VERSION ""

NS_ :

BS_:

BU_: XXX

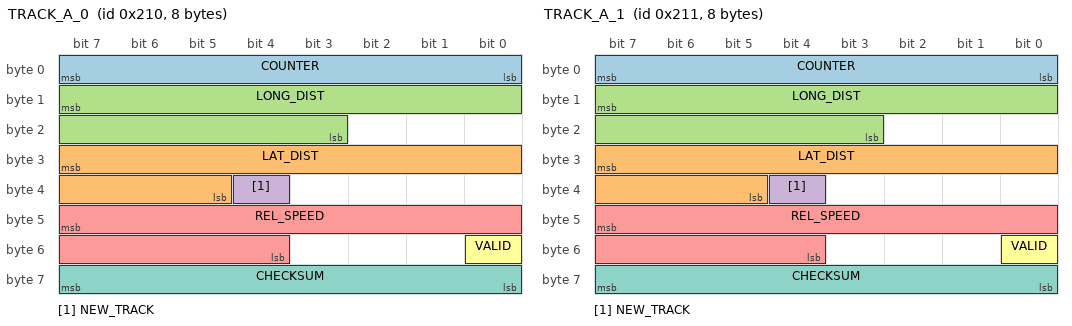
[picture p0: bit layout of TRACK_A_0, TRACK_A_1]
BO_ 528 TRACK_A_0: 8 XXX
 SG_ COUNTER : 7|8@0+ (1,0) [0|255] "" XXX
 SG_ LAT_DIST : 31|11@0- (0.04,0) [-50|50] "m" XXX
 SG_ LONG_DIST : 15|13@0+ (0.04,0) [0|300] "m" XXX
 SG_ NEW_TRACK : 36|1@0+ (1,0) [0|1] "" XXX
 SG_ REL_SPEED : 47|12@0- (0.025,0) [-100|100] "m/s" XXX
 SG_ VALID : 48|1@0+ (1,0) [0|1] "" XXX
 SG_ CHECKSUM : 63|8@0+ (1,0) [0|255] "" XXX

BO_ 529 TRACK_A_1: 8 XXX
 SG_ COUNTER : 7|8@0+ (1,0) [0|255] "" XXX
 SG_ LAT_DIST : 31|11@0- (0.04,0) [-50|50] "m" XXX
 SG_ LONG_DIST : 15|13@0+ (0.04,0) [0|300] "m" XXX
 SG_ NEW_TRACK : 36|1@0+ (1,0) [0|1] "" XXX
 SG_ REL_SPEED : 47|12@0- (0.025,0) [-100|100] "m/s" XXX
 SG_ VALID : 48|1@0+ (1,0) [0|1] "" XXX
 SG_ CHECKSUM : 63|8@0+ (1,0) [0|255] "" XXX

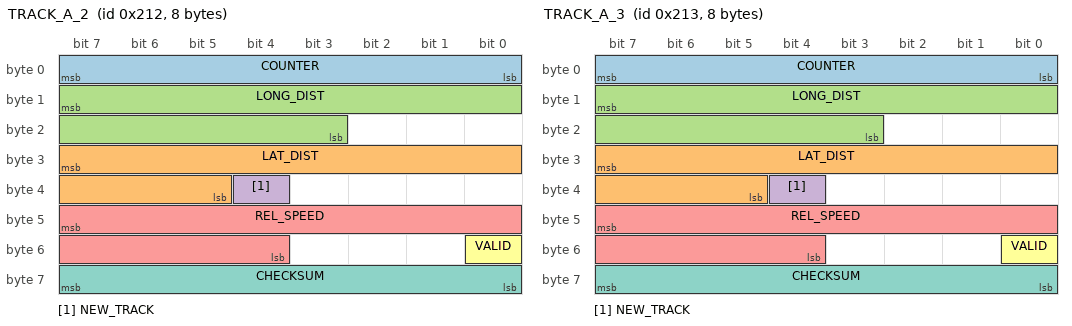
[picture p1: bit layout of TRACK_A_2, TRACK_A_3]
BO_ 530 TRACK_A_2: 8 XXX
 SG_ COUNTER : 7|8@0+ (1,0) [0|255] "" XXX
 SG_ LAT_DIST : 31|11@0- (0.04,0) [-50|50] "m" XXX
 SG_ LONG_DIST : 15|13@0+ (0.04,0) [0|300] "m" XXX
 SG_ NEW_TRACK : 36|1@0+ (1,0) [0|1] "" XXX
 SG_ REL_SPEED : 47|12@0- (0.025,0) [-100|100] "m/s" XXX
 SG_ VALID : 48|1@0+ (1,0) [0|1] "" XXX
 SG_ CHECKSUM : 63|8@0+ (1,0) [0|255] "" XXX

BO_ 531 TRACK_A_3: 8 XXX
 SG_ COUNTER : 7|8@0+ (1,0) [0|255] "" XXX
 SG_ LAT_DIST : 31|11@0- (0.04,0) [-50|50] "m" XXX
 SG_ LONG_DIST : 15|13@0+ (0.04,0) [0|300] "m" XXX
 SG_ NEW_TRACK : 36|1@0+ (1,0) [0|1] "" XXX
 SG_ REL_SPEED : 47|12@0- (0.025,0) [-100|100] "m/s" XXX
 SG_ VALID : 48|1@0+ (1,0) [0|1] "" XXX
 SG_ CHECKSUM : 63|8@0+ (1,0) [0|255] "" XXX

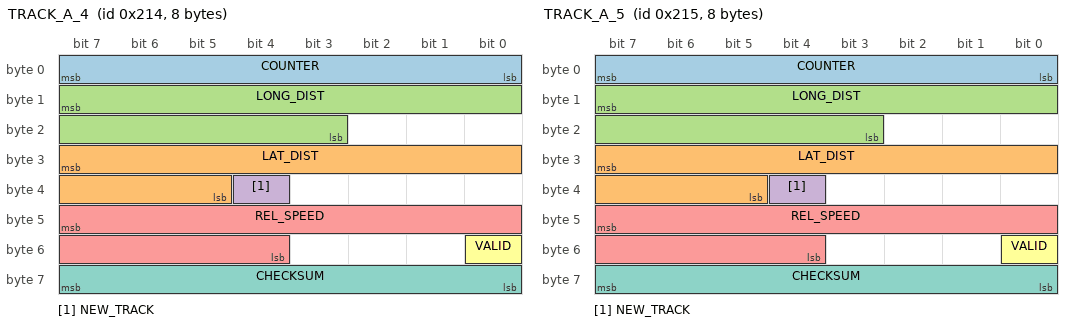
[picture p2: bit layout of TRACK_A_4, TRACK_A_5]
BO_ 532 TRACK_A_4: 8 XXX
 SG_ COUNTER : 7|8@0+ (1,0) [0|255] "" XXX
 SG_ LAT_DIST : 31|11@0- (0.04,0) [-50|50] "m" XXX
 SG_ LONG_DIST : 15|13@0+ (0.04,0) [0|300] "m" XXX
 SG_ NEW_TRACK : 36|1@0+ (1,0) [0|1] "" XXX
 SG_ REL_SPEED : 47|12@0- (0.025,0) [-100|100] "m/s" XXX
 SG_ VALID : 48|1@0+ (1,0) [0|1] "" XXX
 SG_ CHECKSUM : 63|8@0+ (1,0) [0|255] "" XXX

BO_ 533 TRACK_A_5: 8 XXX
 SG_ COUNTER : 7|8@0+ (1,0) [0|255] "" XXX
 SG_ LAT_DIST : 31|11@0- (0.04,0) [-50|50] "m" XXX
 SG_ LONG_DIST : 15|13@0+ (0.04,0) [0|300] "m" XXX
 SG_ NEW_TRACK : 36|1@0+ (1,0) [0|1] "" XXX
 SG_ REL_SPEED : 47|12@0- (0.025,0) [-100|100] "m/s" XXX
 SG_ VALID : 48|1@0+ (1,0) [0|1] "" XXX
 SG_ CHECKSUM : 63|8@0+ (1,0) [0|255] "" XXX

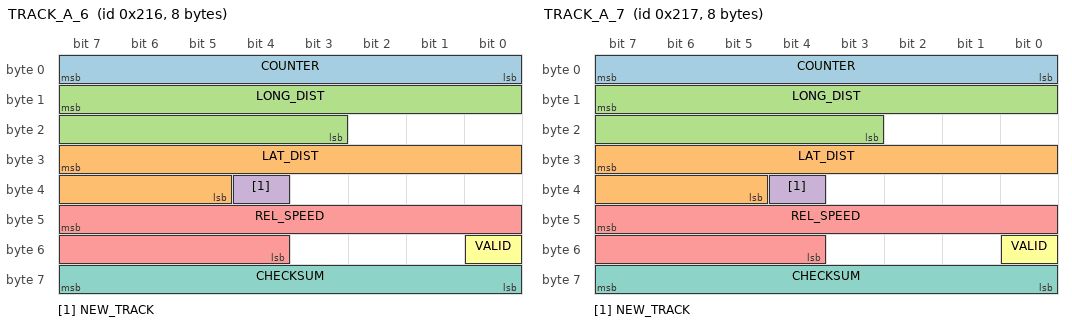
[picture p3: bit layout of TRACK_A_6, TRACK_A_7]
BO_ 534 TRACK_A_6: 8 XXX
 SG_ COUNTER : 7|8@0+ (1,0) [0|255] "" XXX
 SG_ LAT_DIST : 31|11@0- (0.04,0) [-50|50] "m" XXX
 SG_ LONG_DIST : 15|13@0+ (0.04,0) [0|300] "m" XXX
 SG_ NEW_TRACK : 36|1@0+ (1,0) [0|1] "" XXX
 SG_ REL_SPEED : 47|12@0- (0.025,0) [-100|100] "m/s" XXX
 SG_ VALID : 48|1@0+ (1,0) [0|1] "" XXX
 SG_ CHECKSUM : 63|8@0+ (1,0) [0|255] "" XXX

BO_ 535 TRACK_A_7: 8 XXX
 SG_ COUNTER : 7|8@0+ (1,0) [0|255] "" XXX
 SG_ LAT_DIST : 31|11@0- (0.04,0) [-50|50] "m" XXX
 SG_ LONG_DIST : 15|13@0+ (0.04,0) [0|300] "m" XXX
 SG_ NEW_TRACK : 36|1@0+ (1,0) [0|1] "" XXX
 SG_ REL_SPEED : 47|12@0- (0.025,0) [-100|100] "m/s" XXX
 SG_ VALID : 48|1@0+ (1,0) [0|1] "" XXX
 SG_ CHECKSUM : 63|8@0+ (1,0) [0|255] "" XXX

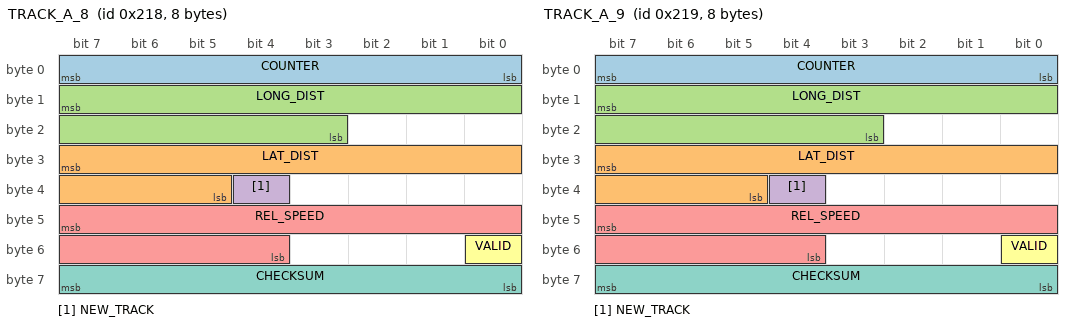
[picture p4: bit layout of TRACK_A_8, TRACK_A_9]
BO_ 536 TRACK_A_8: 8 XXX
 SG_ COUNTER : 7|8@0+ (1,0) [0|255] "" XXX
 SG_ LAT_DIST : 31|11@0- (0.04,0) [-50|50] "m" XXX
 SG_ LONG_DIST : 15|13@0+ (0.04,0) [0|300] "m" XXX
 SG_ NEW_TRACK : 36|1@0+ (1,0) [0|1] "" XXX
 SG_ REL_SPEED : 47|12@0- (0.025,0) [-100|100] "m/s" XXX
 SG_ VALID : 48|1@0+ (1,0) [0|1] "" XXX
 SG_ CHECKSUM : 63|8@0+ (1,0) [0|255] "" XXX

BO_ 537 TRACK_A_9: 8 XXX
 SG_ COUNTER : 7|8@0+ (1,0) [0|255] "" XXX
 SG_ LAT_DIST : 31|11@0- (0.04,0) [-50|50] "m" XXX
 SG_ LONG_DIST : 15|13@0+ (0.04,0) [0|300] "m" XXX
 SG_ NEW_TRACK : 36|1@0+ (1,0) [0|1] "" XXX
 SG_ REL_SPEED : 47|12@0- (0.025,0) [-100|100] "m/s" XXX
 SG_ VALID : 48|1@0+ (1,0) [0|1] "" XXX
 SG_ CHECKSUM : 63|8@0+ (1,0) [0|255] "" XXX

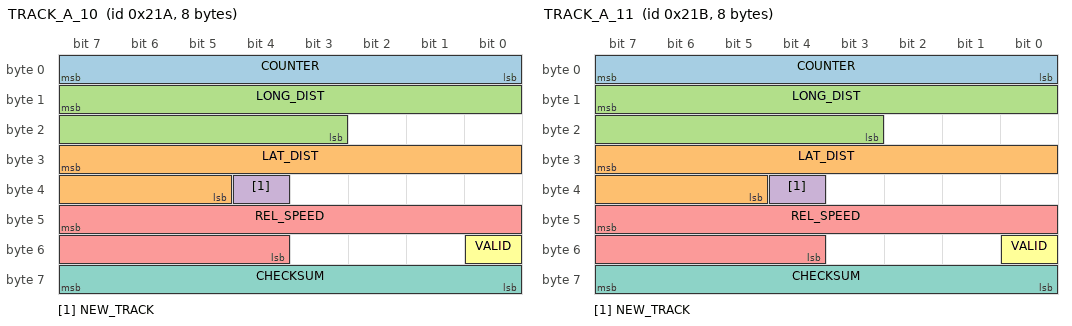
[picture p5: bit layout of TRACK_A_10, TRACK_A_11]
BO_ 538 TRACK_A_10: 8 XXX
 SG_ COUNTER : 7|8@0+ (1,0) [0|255] "" XXX
 SG_ LAT_DIST : 31|11@0- (0.04,0) [-50|50] "m" XXX
 SG_ LONG_DIST : 15|13@0+ (0.04,0) [0|300] "m" XXX
 SG_ NEW_TRACK : 36|1@0+ (1,0) [0|1] "" XXX
 SG_ REL_SPEED : 47|12@0- (0.025,0) [-100|100] "m/s" XXX
 SG_ VALID : 48|1@0+ (1,0) [0|1] "" XXX
 SG_ CHECKSUM : 63|8@0+ (1,0) [0|255] "" XXX

BO_ 539 TRACK_A_11: 8 XXX
 SG_ COUNTER : 7|8@0+ (1,0) [0|255] "" XXX
 SG_ LAT_DIST : 31|11@0- (0.04,0) [-50|50] "m" XXX
 SG_ LONG_DIST : 15|13@0+ (0.04,0) [0|300] "m" XXX
 SG_ NEW_TRACK : 36|1@0+ (1,0) [0|1] "" XXX
 SG_ REL_SPEED : 47|12@0- (0.025,0) [-100|100] "m/s" XXX
 SG_ VALID : 48|1@0+ (1,0) [0|1] "" XXX
 SG_ CHECKSUM : 63|8@0+ (1,0) [0|255] "" XXX

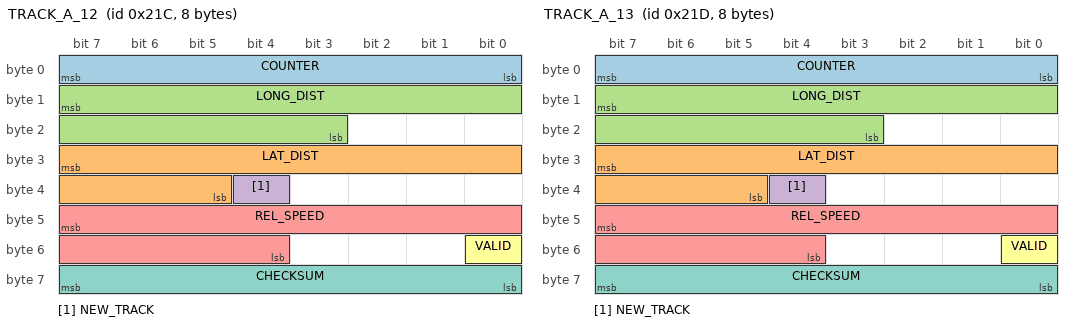
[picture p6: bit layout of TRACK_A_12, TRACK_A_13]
BO_ 540 TRACK_A_12: 8 XXX
 SG_ COUNTER : 7|8@0+ (1,0) [0|255] "" XXX
 SG_ LAT_DIST : 31|11@0- (0.04,0) [-50|50] "m" XXX
 SG_ LONG_DIST : 15|13@0+ (0.04,0) [0|300] "m" XXX
 SG_ NEW_TRACK : 36|1@0+ (1,0) [0|1] "" XXX
 SG_ REL_SPEED : 47|12@0- (0.025,0) [-100|100] "m/s" XXX
 SG_ VALID : 48|1@0+ (1,0) [0|1] "" XXX
 SG_ CHECKSUM : 63|8@0+ (1,0) [0|255] "" XXX

BO_ 541 TRACK_A_13: 8 XXX
 SG_ COUNTER : 7|8@0+ (1,0) [0|255] "" XXX
 SG_ LAT_DIST : 31|11@0- (0.04,0) [-50|50] "m" XXX
 SG_ LONG_DIST : 15|13@0+ (0.04,0) [0|300] "m" XXX
 SG_ NEW_TRACK : 36|1@0+ (1,0) [0|1] "" XXX
 SG_ REL_SPEED : 47|12@0- (0.025,0) [-100|100] "m/s" XXX
 SG_ VALID : 48|1@0+ (1,0) [0|1] "" XXX
 SG_ CHECKSUM : 63|8@0+ (1,0) [0|255] "" XXX

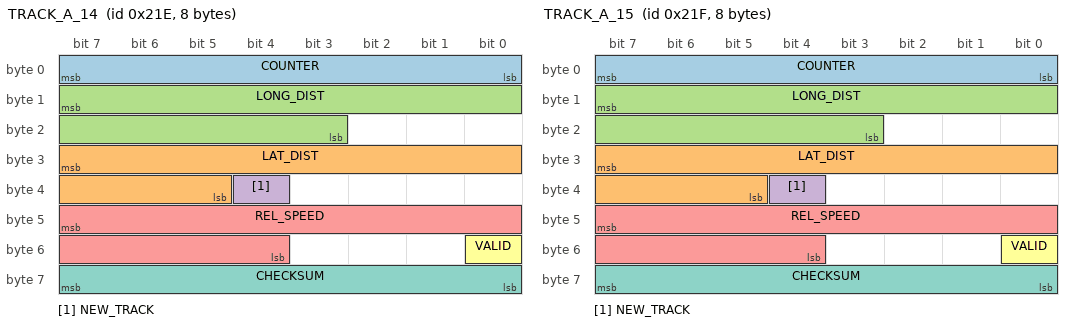
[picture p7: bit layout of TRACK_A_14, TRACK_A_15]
BO_ 542 TRACK_A_14: 8 XXX
 SG_ COUNTER : 7|8@0+ (1,0) [0|255] "" XXX
 SG_ LAT_DIST : 31|11@0- (0.04,0) [-50|50] "m" XXX
 SG_ LONG_DIST : 15|13@0+ (0.04,0) [0|300] "m" XXX
 SG_ NEW_TRACK : 36|1@0+ (1,0) [0|1] "" XXX
 SG_ REL_SPEED : 47|12@0- (0.025,0) [-100|100] "m/s" XXX
 SG_ VALID : 48|1@0+ (1,0) [0|1] "" XXX
 SG_ CHECKSUM : 63|8@0+ (1,0) [0|255] "" XXX

BO_ 543 TRACK_A_15: 8 XXX
 SG_ COUNTER : 7|8@0+ (1,0) [0|255] "" XXX
 SG_ LAT_DIST : 31|11@0- (0.04,0) [-50|50] "m" XXX
 SG_ LONG_DIST : 15|13@0+ (0.04,0) [0|300] "m" XXX
 SG_ NEW_TRACK : 36|1@0+ (1,0) [0|1] "" XXX
 SG_ REL_SPEED : 47|12@0- (0.025,0) [-100|100] "m/s" XXX
 SG_ VALID : 48|1@0+ (1,0) [0|1] "" XXX
 SG_ CHECKSUM : 63|8@0+ (1,0) [0|255] "" XXX

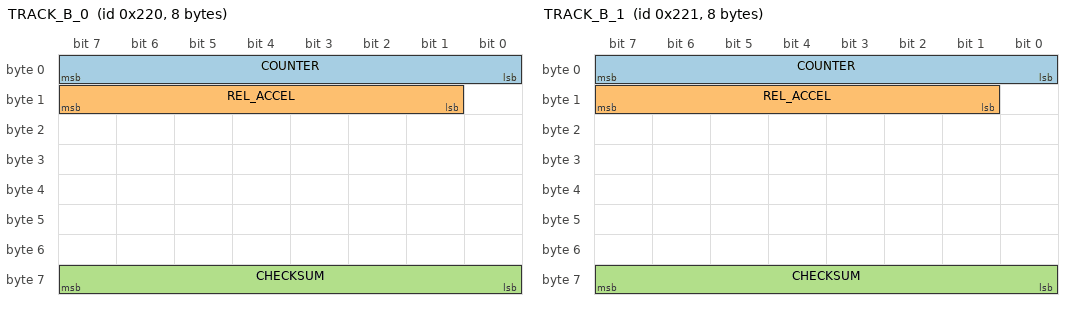
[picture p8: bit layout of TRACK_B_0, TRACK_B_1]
BO_ 544 TRACK_B_0: 8 XXX
 SG_ COUNTER : 7|8@0+ (1,0) [0|255] "" XXX
 SG_ REL_ACCEL : 15|7@0- (1,0) [-64|63] "" XXX
 SG_ CHECKSUM : 63|8@0+ (1,0) [0|255] "" XXX

BO_ 545 TRACK_B_1: 8 XXX
 SG_ COUNTER : 7|8@0+ (1,0) [0|255] "" XXX
 SG_ REL_ACCEL : 15|7@0- (1,0) [-64|63] "" XXX
 SG_ CHECKSUM : 63|8@0+ (1,0) [0|255] "" XXX

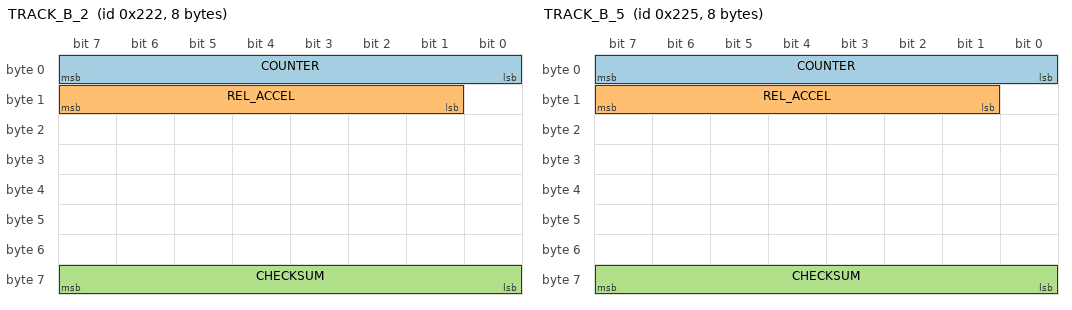
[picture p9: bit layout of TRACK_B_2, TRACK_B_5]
BO_ 546 TRACK_B_2: 8 XXX
 SG_ COUNTER : 7|8@0+ (1,0) [0|255] "" XXX
 SG_ REL_ACCEL : 15|7@0- (1,0) [-64|63] "" XXX
 SG_ CHECKSUM : 63|8@0+ (1,0) [0|255] "" XXX

BO_ 547 undefined: 8 XXX

BO_ 548 undefined: 8 XXX

BO_ 549 TRACK_B_5: 8 XXX
 SG_ COUNTER : 7|8@0+ (1,0) [0|255] "" XXX
 SG_ REL_ACCEL : 15|7@0- (1,0) [-64|63] "" XXX
 SG_ CHECKSUM : 63|8@0+ (1,0) [0|255] "" XXX

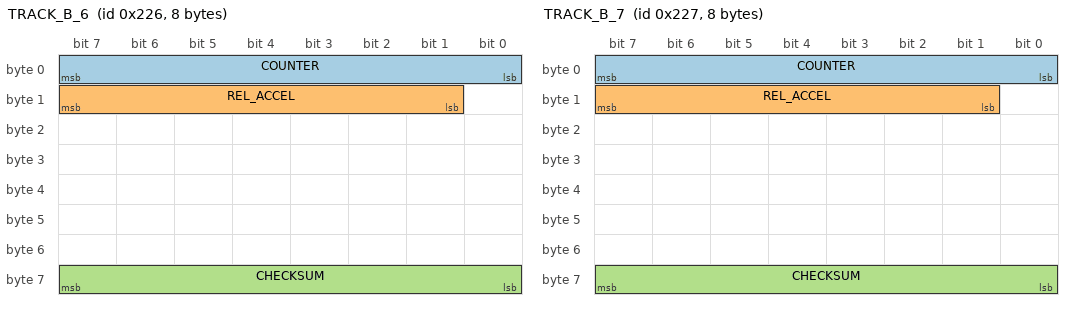
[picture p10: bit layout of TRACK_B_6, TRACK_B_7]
BO_ 550 TRACK_B_6: 8 XXX
 SG_ COUNTER : 7|8@0+ (1,0) [0|255] "" XXX
 SG_ REL_ACCEL : 15|7@0- (1,0) [-64|63] "" XXX
 SG_ CHECKSUM : 63|8@0+ (1,0) [0|255] "" XXX

BO_ 551 TRACK_B_7: 8 XXX
 SG_ COUNTER : 7|8@0+ (1,0) [0|255] "" XXX
 SG_ REL_ACCEL : 15|7@0- (1,0) [-64|63] "" XXX
 SG_ CHECKSUM : 63|8@0+ (1,0) [0|255] "" XXX

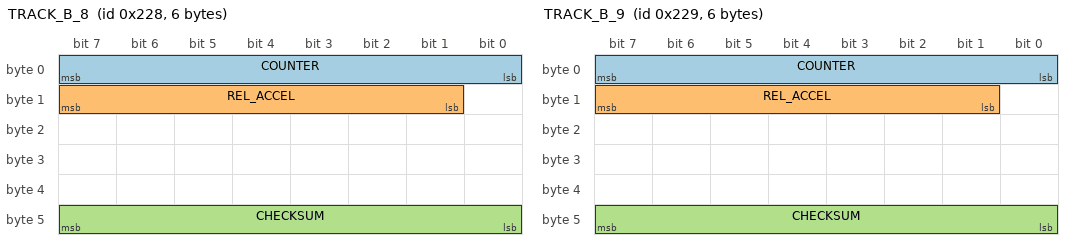
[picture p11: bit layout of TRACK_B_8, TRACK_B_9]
BO_ 552 TRACK_B_8: 6 XXX
 SG_ COUNTER : 7|8@0+ (1,0) [0|255] "" XXX
 SG_ REL_ACCEL : 15|7@0- (1,0) [-64|63] "" XXX
 SG_ CHECKSUM : 47|8@0+ (1,0) [0|255] "" XXX

BO_ 553 TRACK_B_9: 6 XXX
 SG_ COUNTER : 7|8@0+ (1,0) [0|255] "" XXX
 SG_ REL_ACCEL : 15|7@0- (1,0) [-64|63] "" XXX
 SG_ CHECKSUM : 47|8@0+ (1,0) [0|255] "" XXX

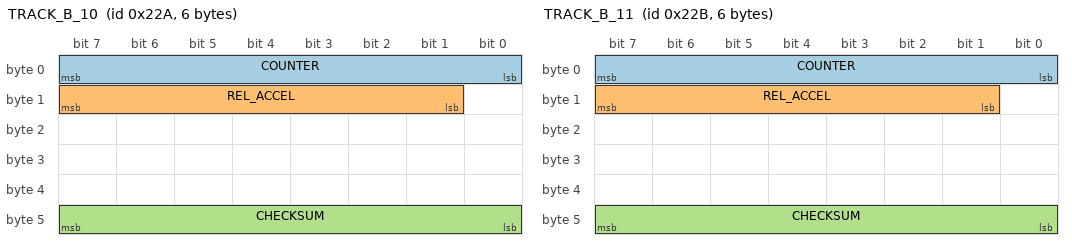
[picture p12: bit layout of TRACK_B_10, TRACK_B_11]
BO_ 554 TRACK_B_10: 6 XXX
 SG_ COUNTER : 7|8@0+ (1,0) [0|255] "" XXX
 SG_ REL_ACCEL : 15|7@0- (1,0) [-64|63] "" XXX
 SG_ CHECKSUM : 47|8@0+ (1,0) [0|255] "" XXX

BO_ 555 TRACK_B_11: 6 XXX
 SG_ COUNTER : 7|8@0+ (1,0) [0|255] "" XXX
 SG_ REL_ACCEL : 15|7@0- (1,0) [-64|63] "" XXX
 SG_ CHECKSUM : 47|8@0+ (1,0) [0|255] "" XXX

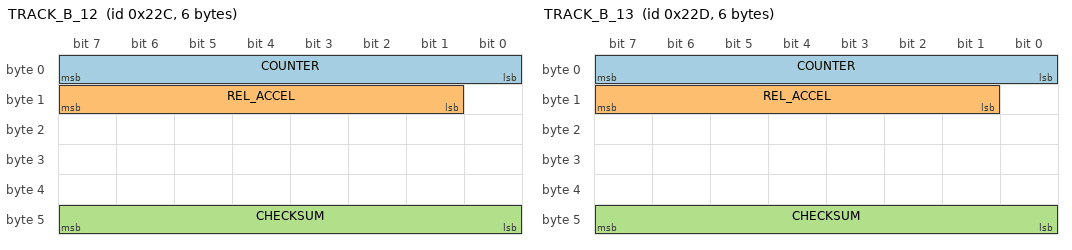
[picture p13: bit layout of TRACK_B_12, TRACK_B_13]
BO_ 556 TRACK_B_12: 6 XXX
 SG_ COUNTER : 7|8@0+ (1,0) [0|255] "" XXX
 SG_ REL_ACCEL : 15|7@0- (1,0) [-64|63] "" XXX
 SG_ CHECKSUM : 47|8@0+ (1,0) [0|255] "" XXX

BO_ 557 TRACK_B_13: 6 XXX
 SG_ COUNTER : 7|8@0+ (1,0) [0|255] "" XXX
 SG_ REL_ACCEL : 15|7@0- (1,0) [-64|63] "" XXX
 SG_ CHECKSUM : 47|8@0+ (1,0) [0|255] "" XXX

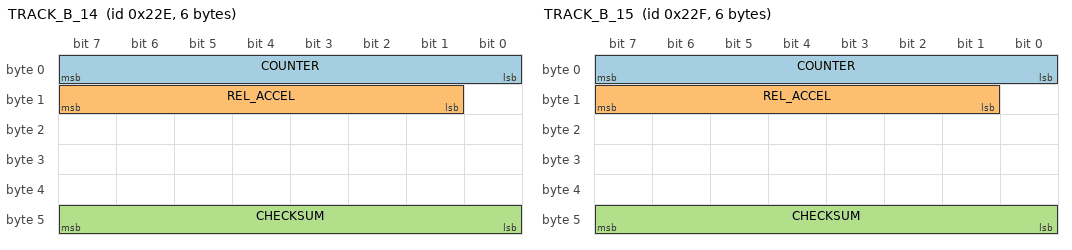
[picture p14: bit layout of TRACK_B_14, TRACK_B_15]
BO_ 558 TRACK_B_14: 6 XXX
 SG_ COUNTER : 7|8@0+ (1,0) [0|255] "" XXX
 SG_ REL_ACCEL : 15|7@0- (1,0) [-64|63] "" XXX
 SG_ CHECKSUM : 47|8@0+ (1,0) [0|255] "" XXX

BO_ 559 TRACK_B_15: 6 XXX
 SG_ COUNTER : 7|8@0+ (1,0) [0|255] "" XXX
 SG_ REL_ACCEL : 15|7@0- (1,0) [-64|63] "" XXX
 SG_ CHECKSUM : 47|8@0+ (1,0) [0|255] "" XXX

BO_ 1552 NEW_MSG_1: 8 XXX
 SG_ SPEED_LOWRES : 16|8@1+ (1,0) [0|255] "km/h?" XXX

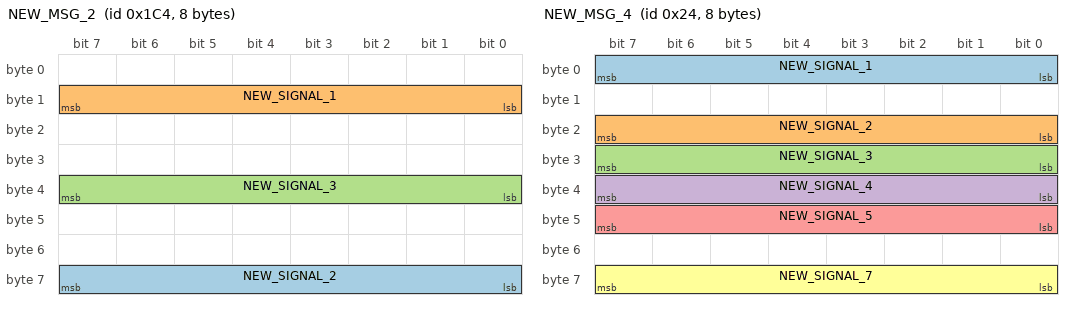
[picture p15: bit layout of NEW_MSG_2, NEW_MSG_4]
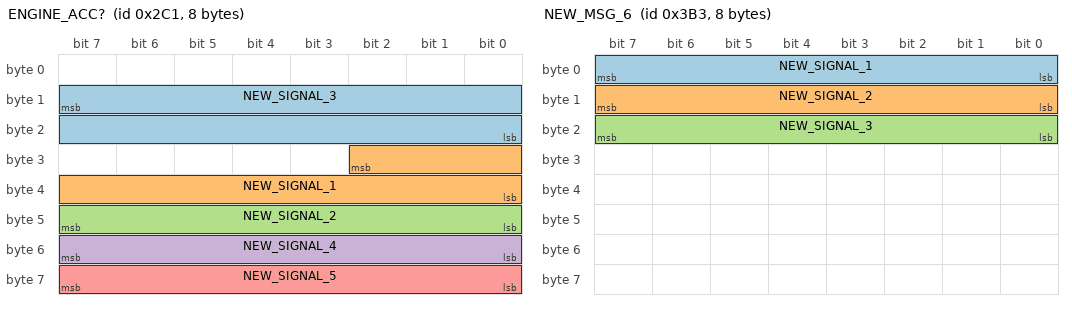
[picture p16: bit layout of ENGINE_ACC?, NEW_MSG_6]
BO_ 452 NEW_MSG_2: 8 XXX
 SG_ NEW_SIGNAL_2 : 56|8@1+ (1,0) [0|255] "" XXX
 SG_ NEW_SIGNAL_1 : 8|8@1+ (1,0) [0|255] "" XXX
 SG_ NEW_SIGNAL_3 : 39|8@0+ (1,0) [0|255] "" XXX

BO_ 37 NEW_MSG_3: 8 XXX
 SG_ NEW_SIGNAL_1 : 15|8@0+ (1,0) [0|255] "" XXX
 SG_ NEW_SIGNAL_2 : 47|8@0+ (1,0) [0|255] "" XXX

BO_ 36 NEW_MSG_4: 8 XXX
 SG_ NEW_SIGNAL_1 : 7|8@0+ (1,0) [0|255] "" XXX
 SG_ NEW_SIGNAL_2 : 23|8@0+ (1,0) [0|255] "" XXX
 SG_ NEW_SIGNAL_3 : 31|8@0+ (1,0) [0|255] "" XXX
 SG_ NEW_SIGNAL_4 : 39|8@0+ (1,0) [0|255] "" XXX
 SG_ NEW_SIGNAL_5 : 47|8@0+ (1,0) [0|255] "" XXX
 SG_ NEW_SIGNAL_7 : 63|8@0+ (1,0) [0|255] "" XXX

BO_ 705 ENGINE_ACC?: 8 XXX
 SG_ NEW_SIGNAL_3 : 15|16@0+ (1,0) [0|255] "" XXX
 SG_ NEW_SIGNAL_1 : 26|11@0+ (1,0) [0|255] "" XXX
 SG_ NEW_SIGNAL_2 : 47|8@0+ (1,0) [0|255] "" XXX
 SG_ NEW_SIGNAL_4 : 55|8@0+ (1,0) [0|255] "" XXX
 SG_ NEW_SIGNAL_5 : 63|8@0+ (1,0) [0|255] "" XXX

BO_ 947 NEW_MSG_6: 8 XXX
 SG_ NEW_SIGNAL_1 : 7|8@0+ (1,0) [0|255] "" XXX
 SG_ NEW_SIGNAL_2 : 15|8@0+ (1,0) [0|255] "" XXX
 SG_ NEW_SIGNAL_3 : 23|8@0+ (1,0) [0|255] "" XXX

BO_ 955 NEW_MSG_7: 8 XXX
 SG_ NEW_SIGNAL_1 : 23|8@0+ (1,0) [0|255] "" XXX

BO_ 1595 CONTAINS_TIME: 8 XXX
 SG_ TIME_ON : 55|16@0+ (0.1,0) [0|65535] "" XXX

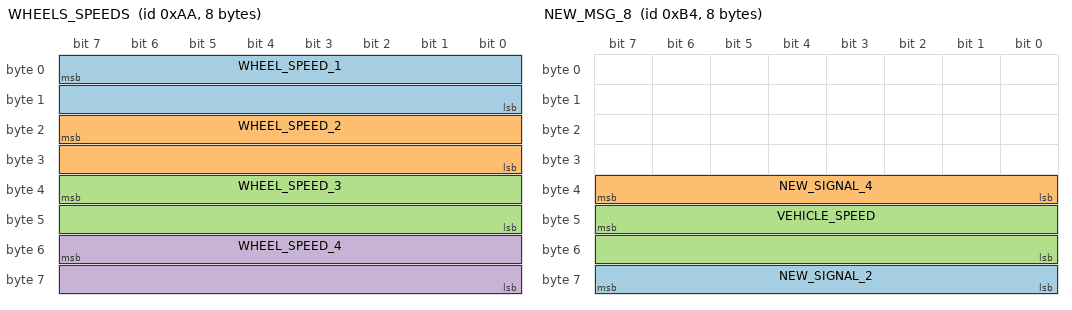
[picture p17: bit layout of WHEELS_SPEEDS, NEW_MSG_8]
BO_ 170 WHEELS_SPEEDS: 8 XXX
 SG_ WHEEL_SPEED_1 : 7|16@0+ (0.01,-67.67) [0|65535] "" XXX
 SG_ WHEEL_SPEED_2 : 23|16@0+ (0.01,-67.67) [0|65535] "km/h?" XXX
 SG_ WHEEL_SPEED_3 : 39|16@0+ (0.01,-67.67) [0|65535] "km/h" XXX
 SG_ WHEEL_SPEED_4 : 55|16@0+ (0.01,-67.67) [0|65535] "km/h" XXX

BO_ 180 NEW_MSG_8: 8 XXX
 SG_ NEW_SIGNAL_2 : 63|8@0+ (1,0) [0|255] "" XXX
 SG_ NEW_SIGNAL_4 : 39|8@0+ (1,0) [0|255] "" XXX
 SG_ VEHICLE_SPEED : 47|16@0+ (0.01,0) [0|255] "km/h?" XXX

BO_ 186 NEW_MSG_9: 8 XXX
 SG_ NEW_SIGNAL_1 : 7|16@0+ (1,0) [0|255] "" XXX
 SG_ NEW_SIGNAL_2 : 31|8@0+ (1,0) [0|255] "" XXX

BO_ 565 NEW_MSG_10: 8 XXX

BO_ 464 NEW_MSG_11: 8 XXX

BO_ 426 NEW_MSG_5: 8 XXX
 SG_ NEW_SIGNAL_1 : 47|8@0+ (1,0) [0|255] "" XXX

BO_ 906 NEW_MSG_12: 8 XXX
 SG_ NEW_SIGNAL_1 : 7|8@0+ (1,0) [0|255] "" XXX

BO_ 979 NEW_MSG_13: 8 XXX
 SG_ NEW_SIGNAL_1 : 7|8@0+ (1,0) [0|255] "" XXX
 SG_ NEW_SIGNAL_2 : 15|8@0+ (1,0) [0|255] "" XXX

BO_ 1600 NEW_MSG_14: 8 XXX
 SG_ NEW_SIGNAL_1 : 47|8@0+ (1,0) [0|1] "" XXX

CM_ SG_ 1552 SPEED_LOWRES "Looks like positive speed";
CM_ SG_ 37 NEW_SIGNAL_1 "vehicle orientation? (Z axis, noisy)";
CM_ SG_ 705 NEW_SIGNAL_3 "Maybe not well defined, RPM engine?";
CM_ SG_ 705 NEW_SIGNAL_1 "Maybe not welll defined, acceleration?";
CM_ SG_ 1595 TIME_ON "linear to seconds, must find bounds";
CM_ SG_ 170 WHEEL_SPEED_1 "TB verified";
CM_ SG_ 170 WHEEL_SPEED_2 "to be verified";
CM_ SG_ 170 WHEEL_SPEED_3 "to be verified";
CM_ SG_ 170 WHEEL_SPEED_4 "to be verified";
CM_ SG_ 180 VEHICLE_SPEED "To be confirmed, but only psitive showing for now.";
